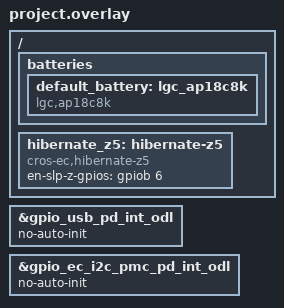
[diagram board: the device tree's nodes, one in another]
/* Copyright 2025 The ChromiumOS Authors
 * Use of this source code is governed by a BSD-style license that can be
 * found in the LICENSE file.
 */

/* Brtk program common DTS includes */

#include <cros/integrated_fwid.dtsi>

#include "rtk_adc.dtsi"
#include "brtk.dtsi"
#include "rtk_fan.dtsi"
#include "rtk_gpio.dtsi"
#include "rtk_i2c.dtsi"
#include "rtk_interrupts.dtsi"
#include "rtk_led_pins.dtsi"
#include "../led_policy.dtsi"
#include "rtk_keyboard.dtsi"
#include "../motionsense.dtsi"
#include "rtk_power_signals.dtsi"
#include "rtk_pwm.dtsi"
#include "../temp_sensors.dtsi"
#include "rtk_usb_typec.dtsi"
#include "../usba.dtsi"

/* Brtk project DTS includes*/

/* Brtk overrides follow... */

/{
        batteries {
                default_battery: lgc_ap18c8k {
                        compatible = "lgc,ap18c8k", "battery-smart";
                };
        };

	hibernate_z5: hibernate-z5 {
		compatible = "cros-ec,hibernate-z5";
		en-slp-z-gpios = <&gpiob 6 GPIO_ACTIVE_HIGH>;
	};
};

/* These GPIOS are initialized by the PDC driver */
&gpio_usb_pd_int_odl {
	no-auto-init;
};
&gpio_ec_i2c_pmc_pd_int_odl {
	no-auto-init;
};
